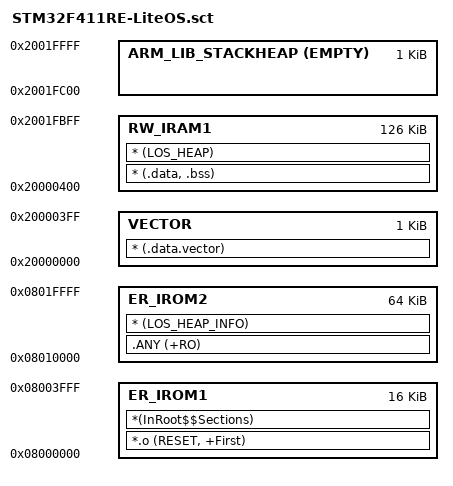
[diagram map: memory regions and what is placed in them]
; *************************************************************
; *** Scatter-Loading Description File generated by uVision ***
; *************************************************************

LR_IROM1 0x08000000 0x0004000  {    ; load region size_region
    ER_IROM1 0x08000000 0x004000  {    ; load address = execution address
        *.o (RESET, +First)
        *(InRoot$$Sections)
    }
}

LR_IROM2 0x08010000 0x0010000  {    ; load region size_region
    ER_IROM2 0x08010000 0x0010000  {    ; load address = execution address
        .ANY (+RO)
        * (LOS_HEAP_INFO)
    }
    VECTOR 0x20000000 0x400  {    ; Vector
        * (.data.vector)
    }
    RW_IRAM1 0x20000400 0x0001F800  {    ; RW data
        ;.ANY (+RW +ZI)
        * (.data, .bss)
        * (LOS_HEAP)
    }
    ARM_LIB_STACKHEAP 0x2001FC00 EMPTY 0x400  {    ;LiteOS MSP

    }
}
